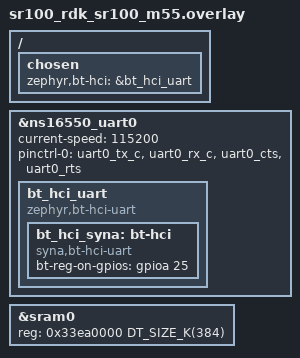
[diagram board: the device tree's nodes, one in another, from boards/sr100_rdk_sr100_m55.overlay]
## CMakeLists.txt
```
# Copyright (c) 2026 Synaptics Incorporated
#
# SPDX-License-Identifier: Apache-2.0

cmake_minimum_required(VERSION 3.20.0)
find_package(Zephyr REQUIRED HINTS $ENV{ZEPHYR_BASE})
project(peripheral_syna_ots)

target_sources(app PRIVATE
	src/main.c
)
```

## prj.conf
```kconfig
# Copyright (c) 2026 Synaptics Incorporated
#
# SPDX-License-Identifier: Apache-2.0

# ── Bluetooth ────────────────────────────────────────────────────────────────
CONFIG_BT=y
CONFIG_BT_PERIPHERAL=y
CONFIG_BT_DEVICE_NAME="Zephyr OTS SR110"
CONFIG_BT_OTS=y
CONFIG_BT_OTS_DIR_LIST_OBJ=y
CONFIG_BT_OTS_OBJ_NAME_WRITE_SUPPORT=y
CONFIG_BT_OTS_OACP_WRITE_SUPPORT=y
CONFIG_BT_OTS_OACP_PATCH_SUPPORT=y
CONFIG_BT_OTS_OACP_CREATE_SUPPORT=y
CONFIG_BT_OTS_OACP_DELETE_SUPPORT=y
CONFIG_BT_OTS_OACP_CHECKSUM_SUPPORT=y
CONFIG_BT_OTS_OBJECT_CHANGED_SUPPORT=y

# ── Console ──────────────────────────────────────────────────────────────────
CONFIG_CONSOLE=y
CONFIG_UART_CONSOLE=y

# ── Logging ──────────────────────────────────────────────────────────────────
CONFIG_LOG=y
#CONFIG_LOG_DEFAULT_LEVEL=2
CONFIG_LOG_PRINTK=y

CONFIG_ASSERT=y

# Console input for interactive menu
CONFIG_CONSOLE_SUBSYS=y
CONFIG_CONSOLE_GETCHAR=y

# BT init + patchram download is sensitive to UART/RX buffering
CONFIG_BT_RX_STACK_SIZE=4096

# ── SR110 + SYNA hardware ──────────────────────────────────────────────────
CONFIG_BT_H4=y
CONFIG_BT_HCI_SYNA=y
CONFIG_BT_HCI_SYNA_BAUD_RATE=3000000
CONFIG_GPIO=y
CONFIG_UART_INTERRUPT_DRIVEN=y
CONFIG_MAIN_STACK_SIZE=4096
CONFIG_BT_BUF_CMD_TX_SIZE=255
CONFIG_BT_BUF_EVT_RX_SIZE=255
CONFIG_UART_NS16550_VARIANT_NS16750=y
# ── BT Buffer and L2CAP MTU configuration ──────────────────────────────────
# CONFIG_BT_OTS_L2CAP_CHAN_TX_MTU defaults to 256 bytes, but without the
# overrides below the ACL/L2CAP TX path falls back to tiny Zephyr defaults
# (BT_BUF_ACL_TX_SIZE=27, BT_L2CAP_TX_MTU=65). That forces every OTS object
# data K-frame to be fragmented into ~10 undersized ACL packets, which was
# observed to trigger a controller "Hardware error" (hardware code 0) on the
# BCM4381A1 during L2CAP CoC object reads. Size the buffers to match the
# 256-byte OTS channel MTU (mirrors central_syna_otc/prj.conf).
CONFIG_BT_BUF_ACL_RX_SIZE=255
CONFIG_BT_BUF_ACL_TX_SIZE=255
CONFIG_BT_BUF_ACL_TX_COUNT=6
CONFIG_BT_L2CAP_TX_MTU=256
CONFIG_BT_L2CAP_TX_BUF_COUNT=8

# ── Per-object size / object count (see also src/main.c) ───────────────────
# The size of a single OTS object and the number of objects the server can
# hold at once are two SEPARATE knobs:
#   - OBJ_MAX_SIZE (defined in src/main.c, currently 1024 bytes) sets the
#     max size of a single object's data buffer. It is a sample-only define,
#     not part of the Zephyr OTS stack.
#   - CONFIG_BT_OTS_MAX_OBJ_CNT (below, default 5) sets how many objects the
#     OTS instance can manage at once.
# Static RAM used by the demo object pool is roughly:
#   OBJ_MAX_SIZE * CONFIG_BT_OTS_MAX_OBJ_CNT (+ per-object metadata)
# Increase either value if you need bigger or more objects, but check your
# available SRAM budget first — raising either one directly increases the
# static memory footprint. (Protocol-wise, object size can go up to 2^16-1
# per Zephyr's net_buf-based Kconfig help text; 1024 here is just what the
# sample hard-codes.)
#
# NOTE: CONFIG_BT_OTS_MAX_OBJ_CNT counts ALL objects in the shared pool,
# including the Directory Listing Object, which is auto-reserved because
# CONFIG_BT_OTS_DIR_LIST_OBJ=y is enabled above. So with N configured here,
# only N-1 slots are actually available for user-created objects via
# bt_ots_obj_add() (e.g. add_photo_object()). This was confirmed on real
# hardware: setting N=5 only allows 4 objects to be created.
CONFIG_BT_OTS_MAX_OBJ_CNT=0x05
CONFIG_XIP=n
```

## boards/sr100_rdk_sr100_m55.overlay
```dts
/*
 * Copyright (c) 2026 Synaptics Incorporated
 *
 * SPDX-License-Identifier: Apache-2.0
 */

/ {
	chosen {
		zephyr,bt-hci = &bt_hci_uart;
	};
};

&ns16550_uart0 {
	status = "okay";
	current-speed = <115200>;
	pinctrl-0 = <&uart0_tx_c &uart0_rx_c &uart0_cts &uart0_rts>;
	pinctrl-names = "default";

	bt_hci_uart: bt_hci_uart {
		compatible = "zephyr,bt-hci-uart";
		status = "okay";

		bt_hci_syna: bt-hci {
			compatible = "syna,bt-hci-uart";
			status = "okay";
			bt-reg-on-gpios = <&gpioa 25 GPIO_ACTIVE_HIGH>;
		};
	};
};

&sram0 {
	reg = <0x33ea0000 DT_SIZE_K(384)>;
	ranges = <0x0 0x33ea0000 DT_SIZE_K(384)>;
};
```

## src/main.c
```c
/*
 * Copyright (c) 2026 Synaptics Incorporated
 *
 * SPDX-License-Identifier: Apache-2.0
 */

#include <zephyr/types.h>
#include <string.h>
#include <errno.h>
#include <zephyr/sys/printk.h>
#include <zephyr/kernel.h>

#include <zephyr/bluetooth/bluetooth.h>
#include <zephyr/bluetooth/conn.h>
#include <zephyr/bluetooth/gatt.h>
#include <zephyr/bluetooth/hci.h>

#include <zephyr/bluetooth/services/ots.h>
#include <zephyr/console/console.h>

#define DEVICE_NAME      CONFIG_BT_DEVICE_NAME
#define DEVICE_NAME_LEN  (sizeof(DEVICE_NAME) - 1)

#define OBJ_POOL_SIZE CONFIG_BT_OTS_MAX_OBJ_CNT
#define OBJ_MAX_SIZE  1024

static const struct bt_data ad[] = {
	BT_DATA_BYTES(BT_DATA_FLAGS, (BT_LE_AD_GENERAL | BT_LE_AD_NO_BREDR)),
	BT_DATA(BT_DATA_NAME_COMPLETE, DEVICE_NAME, DEVICE_NAME_LEN),
};

static const struct bt_data sd[] = {
	BT_DATA_BYTES(BT_DATA_UUID16_ALL, BT_UUID_16_ENCODE(BT_UUID_OTS_VAL)),
};

static struct {
	uint8_t data[OBJ_MAX_SIZE];
	char name[CONFIG_BT_OTS_OBJ_MAX_NAME_LEN + 1];
	uint32_t cur_size;
} objects[OBJ_POOL_SIZE];
static uint32_t obj_cnt;

struct object_creation_data {
	struct bt_ots_obj_size size;
	char *name;
	uint32_t props;
};

#define OTS_OBJ_ID_TO_OBJ_IDX(id) (((id) - BT_OTS_OBJ_ID_MIN) % ARRAY_SIZE(objects))

static struct object_creation_data *object_being_created;
static struct bt_ots *g_ots;

static void connected(struct bt_conn *conn, uint8_t err)
{
	if (err) {
		printk("Connection failed, err %u %s\n", err, bt_hci_err_to_str(err));
		return;
	}

	printk("Connected\n");
}

static void disconnected(struct bt_conn *conn, uint8_t reason)
{
	printk("Disconnected, reason %u %s\n", reason, bt_hci_err_to_str(reason));
}

BT_CONN_CB_DEFINE(conn_callbacks) = {
	.connected = connected,
	.disconnected = disconnected,
};

static int ots_obj_created(struct bt_ots *ots, struct bt_conn *conn, uint64_t id,
			   const struct bt_ots_obj_add_param *add_param,
			   struct bt_ots_obj_created_desc *created_desc)
{
	char id_str[BT_OTS_OBJ_ID_STR_LEN];
	uint64_t index;

	bt_ots_obj_id_to_str(id, id_str, sizeof(id_str));

	if (obj_cnt >= ARRAY_SIZE(objects)) {
		printk("No item from Object pool is available for Object "
		       "with %s ID\n", id_str);
		return -ENOMEM;
	}

	if (add_param->size > OBJ_MAX_SIZE) {
		printk("Object pool item is too small for Object with %s ID\n",
		       id_str);
		return -ENOMEM;
	}

	if (object_being_created) {
		created_desc->name = object_being_created->name;
		created_desc->size = object_being_created->size;
		created_desc->props = object_being_created->props;
	} else {
		/* OTC dynamically created object - name must be empty string at creation */
		index = OTS_OBJ_ID_TO_OBJ_IDX(id);

		objects[index].name[0] = '\0';

		created_desc->name = objects[index].name;
		created_desc->size.alloc = OBJ_MAX_SIZE;
		created_desc->size.cur = 0;
		BT_OTS_OBJ_SET_PROP_READ(created_desc->props);
		BT_OTS_OBJ_SET_PROP_WRITE(created_desc->props);
		BT_OTS_OBJ_SET_PROP_PATCH(created_desc->props);
		BT_OTS_OBJ_SET_PROP_DELETE(created_desc->props);
	}

	printk("Object with %s ID has been created\n", id_str);
	obj_cnt++;

	return 0;
}

static int ots_obj_deleted(struct bt_ots *ots, struct bt_conn *conn,
			    uint64_t id)
{
	char id_str[BT_OTS_OBJ_ID_STR_LEN];

	bt_ots_obj_id_to_str(id, id_str, sizeof(id_str));

	printk("Object with %s ID has been deleted\n", id_str);

	obj_cnt--;

	return 0;
}

static void ots_obj_selected(struct bt_ots *ots, struct bt_conn *conn,
			     uint64_t id)
{
	char id_str[BT_OTS_OBJ_ID_STR_LEN];

	bt_ots_obj_id_to_str(id, id_str, sizeof(id_str));

	printk("Object with %s ID has been selected\n", id_str);
}

static ssize_t ots_obj_read(struct bt_ots *ots, struct bt_conn *conn,
			    uint64_t id, void **data, size_t len,
			    off_t offset)
{
	char id_str[BT_OTS_OBJ_ID_STR_LEN];
	uint32_t obj_index = OTS_OBJ_ID_TO_OBJ_IDX(id);

	bt_ots_obj_id_to_str(id, id_str, sizeof(id_str));

	if (!data) {
		printk("Object with %s ID has been successfully read\n",
		       id_str);

		return 0;
	}

	*data = &objects[obj_index].data[offset];

	/* Send even-indexed objects in 20 byte packets
	 * to demonstrate fragmented transmission.
	 */
	if ((obj_index % 2) == 0) {
		len = (len < 20) ? len : 20;
	}

	printk("Object with %s ID is being read\n"
		"Offset = %lu, Length = %zu\n",
		id_str, (long)offset, len);

	return len;
}

static ssize_t ots_obj_write(struct bt_ots *ots, struct bt_conn *conn,
			     uint64_t id, const void *data, size_t len,
			     off_t offset, size_t rem)
{
	char id_str[BT_OTS_OBJ_ID_STR_LEN];
	uint32_t obj_index = OTS_OBJ_ID_TO_OBJ_IDX(id);

	bt_ots_obj_id_to_str(id, id_str, sizeof(id_str));

	printk("Object with %s ID is being written\n"
		"Offset = %lu, Length = %zu, Remaining= %zu\n",
		id_str, (long)offset, len, rem);

	(void)memcpy(&objects[obj_index].data[offset], data, len);

	if (rem == 0) {
		objects[obj_index].cur_size = (uint32_t)(offset + len);
		printk("Object with %s ID write complete, total %u bytes\n",
		       id_str, objects[obj_index].cur_size);
	}

	return len;
}

static void ots_obj_name_written(struct bt_ots *ots, struct bt_conn *conn,
				 uint64_t id, const char *cur_name, const char *new_name)
{
	char id_str[BT_OTS_OBJ_ID_STR_LEN];
	uint32_t obj_index = OTS_OBJ_ID_TO_OBJ_IDX(id);

	bt_ots_obj_id_to_str(id, id_str, sizeof(id_str));

	printk("Object %s name changed: '%s' -> '%s'\n", id_str, cur_name, new_name);

	strncpy(objects[obj_index].name, new_name, CONFIG_BT_OTS_OBJ_MAX_NAME_LEN);
	objects[obj_index].name[CONFIG_BT_OTS_OBJ_MAX_NAME_LEN] = '\0';
}

static int ots_obj_cal_checksum(struct bt_ots *ots, struct bt_conn *conn, uint64_t id,
				off_t offset, size_t len, void **data)
{
	uint32_t obj_index = OTS_OBJ_ID_TO_OBJ_IDX(id);

	if (obj_index >= OBJ_POOL_SIZE) {
		return -ENOENT;
	}

	*data = &objects[obj_index].data[offset];
	return 0;
}

static struct bt_ots_cb ots_callbacks = {
	.obj_created = ots_obj_created,
	.obj_deleted = ots_obj_deleted,
	.obj_selected = ots_obj_selected,
	.obj_read = ots_obj_read,
	.obj_write = ots_obj_write,
	.obj_name_written = ots_obj_name_written,
	.obj_cal_checksum = ots_obj_cal_checksum,
};

static int ots_init(void)
{
	int err;
	struct bt_ots *ots;
	struct object_creation_data obj_data;
	struct bt_ots_init_param ots_init;
	struct bt_ots_obj_add_param param;
	const char * const first_object_name = "first_object.txt";
	const char * const second_object_name = "second_object.gif";
	uint32_t cur_size;
	uint32_t alloc_size;

	ots = bt_ots_free_instance_get();
	if (!ots) {
		printk("Failed to retrieve OTS instance\n");
		return -ENOMEM;
	}
	g_ots = ots;

	/* Configure OTS initialization. */
	(void)memset(&ots_init, 0, sizeof(ots_init));
	BT_OTS_OACP_SET_FEAT_READ(ots_init.features.oacp);
	BT_OTS_OACP_SET_FEAT_WRITE(ots_init.features.oacp);
	BT_OTS_OACP_SET_FEAT_CREATE(ots_init.features.oacp);
	BT_OTS_OACP_SET_FEAT_DELETE(ots_init.features.oacp);
	BT_OTS_OACP_SET_FEAT_PATCH(ots_init.features.oacp);
	BT_OTS_OLCP_SET_FEAT_GO_TO(ots_init.features.olcp);
	ots_init.cb = &ots_callbacks;

	/* Initialize OTS instance. */
	err = bt_ots_init(ots, &ots_init);
	if (err) {
		printk("Failed to init OTS (err:%d)\n", err);
		return err;
	}

	/* Prepare first object demo data and add it to the instance. */
	cur_size = sizeof(objects[0].data) / 2;
	alloc_size = sizeof(objects[0].data);
	for (uint32_t i = 0; i < cur_size; i++) {
		objects[0].data[i] = i + 1;
	}

	(void)memset(&obj_data, 0, sizeof(obj_data));
	__ASSERT(strlen(first_object_name) <= CONFIG_BT_OTS_OBJ_MAX_NAME_LEN,
		 "Object name length is larger than the allowed maximum of %u",
		 CONFIG_BT_OTS_OBJ_MAX_NAME_LEN);
	(void)strcpy(objects[0].name, first_object_name);
	obj_data.name = objects[0].name;
	obj_data.size.cur = cur_size;
	obj_data.size.alloc = alloc_size;
	objects[0].cur_size = cur_size;
	BT_OTS_OBJ_SET_PROP_READ(obj_data.props);
	BT_OTS_OBJ_SET_PROP_WRITE(obj_data.props);
	BT_OTS_OBJ_SET_PROP_PATCH(obj_data.props);
	object_being_created = &obj_data;

	param.size = alloc_size;
	param.type.uuid.type = BT_UUID_TYPE_16;
	param.type.uuid_16.val = BT_UUID_OTS_TYPE_UNSPECIFIED_VAL;
	err = bt_ots_obj_add(ots, &param);
	object_being_created = NULL;
	if (err < 0) {
		printk("Failed to add an object to OTS (err: %d)\n", err);
		return err;
	}

	/* Prepare second object demo data and add it to the instance. */
	cur_size = sizeof(objects[0].data);
	alloc_size = sizeof(objects[0].data);
	for (uint32_t i = 0; i < cur_size; i++) {
		objects[1].data[i] = i * 2;
	}

	(void)memset(&obj_data, 0, sizeof(obj_data));
	__ASSERT(strlen(second_object_name) <= CONFIG_BT_OTS_OBJ_MAX_NAME_LEN,
		 "Object name length is larger than the allowed maximum of %u",
		 CONFIG_BT_OTS_OBJ_MAX_NAME_LEN);
	(void)strcpy(objects[1].name, second_object_name);
	obj_data.name = objects[1].name;
	obj_data.size.cur = cur_size;
	obj_data.size.alloc = alloc_size;
	objects[1].cur_size = cur_size;
	BT_OTS_OBJ_SET_PROP_READ(obj_data.props);
	object_being_created = &obj_data;

	param.size = alloc_size;
	param.type.uuid.type = BT_UUID_TYPE_16;
	param.type.uuid_16.val = BT_UUID_OTS_TYPE_UNSPECIFIED_VAL;
	err = bt_ots_obj_add(ots, &param);
	object_being_created = NULL;
	if (err < 0) {
		printk("Failed to add an object to OTS (err: %d)\n", err);
		return err;
	}

	return 0;
}

static void print_object_list(void)
{
	printk("\n========== OTS Object List ==========\n");
	for (uint32_t i = 0; i < obj_cnt; i++) {
		uint64_t id = BT_OTS_OBJ_ID_MIN + i;
		char id_str[BT_OTS_OBJ_ID_STR_LEN];

		bt_ots_obj_id_to_str(id, id_str, sizeof(id_str));
		printk("  [%u] ID=%-20s  alloc=%4u  cur=%4u  name=\"%s\"\n",
		       i, id_str,
		       (unsigned int)sizeof(objects[i].data),
		       (unsigned int)objects[i].cur_size,
		       objects[i].name);
	}
	printk("=====================================\n\n");
}

static int add_photo_object(void)
{
	int err;
	struct bt_ots_obj_add_param param;
	struct object_creation_data obj_data;
	static uint8_t photo_cnt;

	if (obj_cnt >= ARRAY_SIZE(objects)) {
		printk("Object pool full, cannot add more\n");
		return -ENOMEM;
	}

	uint32_t idx = obj_cnt;
	uint32_t alloc_size = OBJ_MAX_SIZE;
	uint32_t cur_size = 64; /* Simulated photo data size */

	/* Fill with dummy photo data */
	for (uint32_t i = 0; i < cur_size; i++) {
		objects[idx].data[i] = (i + photo_cnt) & 0xFF;
	}
	objects[idx].cur_size = cur_size;

	snprintf(objects[idx].name, sizeof(objects[idx].name),
		 "photo_%d.jpg", photo_cnt++);

	(void)memset(&obj_data, 0, sizeof(obj_data));
	obj_data.name = objects[idx].name;
	obj_data.size.cur = cur_size;
	obj_data.size.alloc = alloc_size;
	BT_OTS_OBJ_SET_PROP_READ(obj_data.props);
	BT_OTS_OBJ_SET_PROP_WRITE(obj_data.props);
	BT_OTS_OBJ_SET_PROP_PATCH(obj_data.props);
	BT_OTS_OBJ_SET_PROP_DELETE(obj_data.props);
	object_being_created = &obj_data;

	param.size = alloc_size;
	param.type.uuid.type = BT_UUID_TYPE_16;
	param.type.uuid_16.val = BT_UUID_OTS_TYPE_UNSPECIFIED_VAL;
	err = bt_ots_obj_add(g_ots, &param);
	object_being_created = NULL;
	if (err < 0) {
		printk("Failed to add photo object (err: %d)\n", err);
		return err;
	}

	printk("Photo object '%s' added (id=%d), Object Changed indication sent\n",
	       objects[idx].name, err);
	return 0;
}

int main(void)
{
	int err;

	printk("Starting Bluetooth Peripheral OTS example\n");

	err = bt_enable(NULL);
	if (err) {
		printk("Bluetooth init failed (err %d)\n", err);
		return 0;
	}

	printk("Bluetooth initialized\n");

	err = ots_init();
	if (err) {
		printk("Failed to init OTS (err:%d)\n", err);
		return 0;
	}

	print_object_list();

	err = bt_le_adv_start(BT_LE_ADV_CONN_FAST_1, ad, ARRAY_SIZE(ad), sd, ARRAY_SIZE(sd));
	if (err) {
		printk("Advertising failed to start (err %d)\n", err);
		return 0;
	}

	printk("Advertising successfully started\n");

	console_init();

	printk("\n=== OTS Server Menu ===\n");
	printk("[a] Add photo object (triggers Object Changed)\n");
	printk("[l] List objects\n");
	printk("[q] Quit\n");

	while (1) {
		printk("\nChoice: ");
		int ch = console_getchar();

		if (ch == '\r' || ch == '\n') {
			continue;
		}

		printk("%c\n", ch);

		if (ch == 'a' || ch == 'A') {
			add_photo_object();
		} else if (ch == 'l' || ch == 'L') {
			print_object_list();
		} else if (ch == 'q' || ch == 'Q') {
			printk("Exiting...\n");
			break;
		} else {
			printk("Invalid command!\n");
		}
	}

	return 0;
}
```
